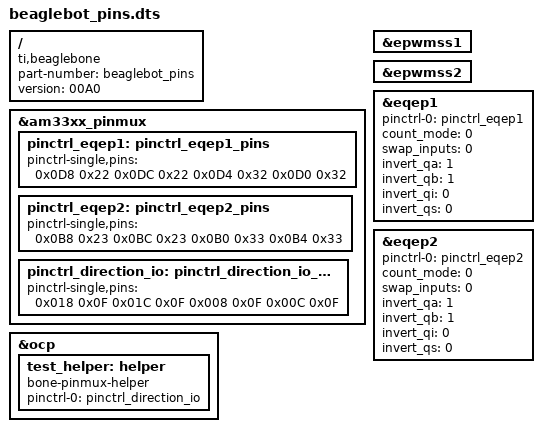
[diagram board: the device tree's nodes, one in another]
/*
 * Copyright (C) 2013 Nathaniel R. Lewis - http://nathanielrlewis.com/
 *
 * This program is free software; you can redistribute it and/or modify
 * it under the terms of the GNU General Public License version 2 as
 * published by the Free Software Foundation.
 * 
 * Enable hardware for beaglebot
 *   - eQEP 1 
 *   - eQEP 2
 *   - Motor controller direction IO lines
 */
/dts-v1/;
/plugin/;

/ {
    compatible = "ti,beaglebone", "ti,beaglebone-black";

    /* identification */
    part-number = "beaglebot_pins";
    version     = "00A0";

    fragment@0 {
        target = <&am33xx_pinmux>;
        __overlay__ {
        	pinctrl_eqep1: pinctrl_eqep1_pins {
                pinctrl-single,pins = <					 				   
                    0x0D8 0x22  /* P8_31 = GPIO0_10 = EQEP1_index, MODE2 */
                    0x0DC 0x22  /* P8_32 = GPIO0_11 = EQEP1_strobe, MODE2 */
                    0x0D4 0x32  /* P8_33 = GPIO0_9 = EQEP1B_in, MODE2 */
                    0x0D0 0x32  /* P8_35 = GPIO0_8 = EQEP1A_in, MODE2 */
                >;
            };
        };
    };
    
    fragment@1 {
        target = <&am33xx_pinmux>;
        __overlay__ {
            pinctrl_eqep2: pinctrl_eqep2_pins {
                pinctrl-single,pins = <					 				   
                    0x0B8 0x23  /* P8_39 = GPIO2_12 = EQEP2_index, MODE3 */
                    0x0BC 0x23  /* P8_40 = GPIO2_13 = EQEP2_strobe, MODE3 */
                    0x0B0 0x33  /* P8_41 = GPIO2_10 = EQEP2A_in, MODE3 */
                    0x0B4 0x33  /* P8_42 = GPIO2_11 = EQEP2B_in, MODE3 */
                >;
            };
        };
    };
    
    fragment@2 {
        target = <&am33xx_pinmux>;
        __overlay__ {
            pinctrl_direction_io: pinctrl_direction_io_pins {
                pinctrl-single,pins = <
                    0x018 0x0F  /* P8_3 = gpmc_ad6 = GPIO1_6, MODE7 */
                    0x01C 0x0F  /* P8_4 = gpmc_ad7 = GPIO1_7, MODE7 */
                    0x008 0x0F  /* P8_5 = gpmc_ad2 = GPIO1_2, MODE7 */
                    0x00C 0x0F  /* P8_6 = gpmc_ad3 = GPIO1_3, MODE7 */
                >;
            };
        };
    };
    
    fragment@3 {
        target = <&epwmss1>;
        __overlay__ {
            status = "okay";
        };
    };
    
    fragment@4 {
        target = <&epwmss2>;
        __overlay__ {
            status = "okay";
        };
    };
    
    fragment@5 {
    	target = <&eqep1>;
    	__overlay__ {
            pinctrl-names = "default";
            pinctrl-0 = <&pinctrl_eqep1>;
            
            count_mode = <0>;  /* 0 - Quadrature mode, normal 90 phase offset cha & chb.  1 - Direction mode.  cha input = clock, chb input = direction */
            swap_inputs = <0>; /* Are channel A and channel B swapped? (0 - no, 1 - yes) */
            invert_qa = <1>;   /* Should we invert the channel A input?  */
            invert_qb = <1>;   /* Should we invert the channel B input? I invert these because my encoder outputs drive transistors that pull down the pins */
            invert_qi = <0>;   /* Should we invert the index input? */
            invert_qs = <0>;   /* Should we invert the strobe input? */
            
	        status = "okay";
    	};
    };
    
    fragment@6 {
    	target = <&eqep2>;
    	__overlay__ {
            pinctrl-names = "default";
            pinctrl-0 = <&pinctrl_eqep2>;
            
            count_mode = <0>;  /* 0 - Quadrature mode, normal 90 phase offset cha & chb.  1 - Direction mode.  cha input = clock, chb input = direction */
            swap_inputs = <0>; /* Are channel A and channel B swapped? (0 - no, 1 - yes) */
            invert_qa = <1>;   /* Should we invert the channel A input?  */
            invert_qb = <1>;   /* Should we invert the channel B input? I invert these because my encoder outputs drive transistors that pull down the pins */
            invert_qi = <0>;   /* Should we invert the index input? */
            invert_qs = <0>;   /* Should we invert the strobe input? */
            
	        status = "okay";
    	};
    };
    
    fragment@7 {
        target = <&ocp>;
        __overlay__ {
            test_helper: helper {
                compatible = "bone-pinmux-helper";
                pinctrl-names = "default";
                pinctrl-0 = <&pinctrl_direction_io>;
                status = "okay";
            };
        };
    };
};
